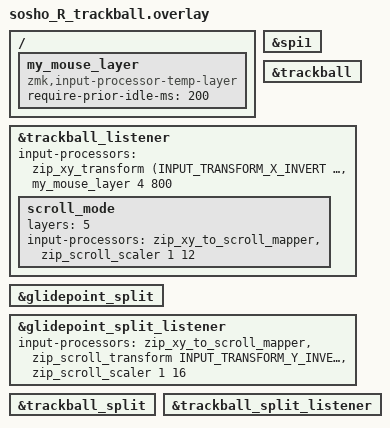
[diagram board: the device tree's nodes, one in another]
#include "sosho_R.dtsi"
#include <input/processors.dtsi>

/ {
    /omit-if-no-ref/ my_mouse_layer: my_mouse_layer {
        compatible = "zmk,input-processor-temp-layer";
        #input-processor-cells = <2>;
        require-prior-idle-ms = <200>;
    };
};

&spi1 { status = "okay"; };
&trackball { status = "okay"; };

&trackball_listener {
    status = "okay";
    input-processors = <
        &zip_xy_transform (INPUT_TRANSFORM_X_INVERT | INPUT_TRANSFORM_Y_INVERT)
        &my_mouse_layer 4 800
    >;

    scroll_mode {
        layers = <5>;
        input-processors = <
            &zip_xy_to_scroll_mapper
            &zip_scroll_scaler 1 12
        >;
    };
};

&glidepoint_split { status = "okay"; };
&glidepoint_split_listener {
    status = "okay";
    input-processors = <
        &zip_xy_to_scroll_mapper
        &zip_scroll_transform INPUT_TRANSFORM_Y_INVERT
        &zip_scroll_scaler 1 16
    >;
};

&trackball_split { status = "okay"; };
&trackball_split_listener { status = "okay"; };
